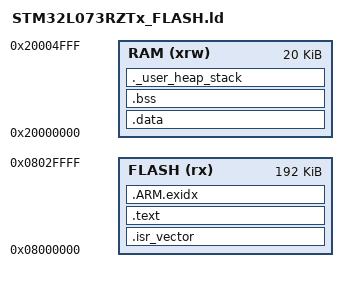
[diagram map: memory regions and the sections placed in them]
/* STM32L073RZT6: 192 KiB Flash and 20 KiB SRAM. */
ENTRY(Reset_Handler)

MEMORY
{
    FLASH (rx)  : ORIGIN = 0x08000000, LENGTH = 192K
    RAM   (xrw) : ORIGIN = 0x20000000, LENGTH = 20K
}

_estack = ORIGIN(RAM) + LENGTH(RAM);

SECTIONS
{
    .isr_vector :
    {
        . = ALIGN(4);
        KEEP(*(.isr_vector))
        . = ALIGN(4);
    } > FLASH

    .text :
    {
        . = ALIGN(4);
        *(.text*)
        *(.rodata*)
        . = ALIGN(4);
        _etext = .;
    } > FLASH

    .ARM.exidx :
    {
        . = ALIGN(4);
        *(.ARM.exidx*)
        . = ALIGN(4);
    } > FLASH

    .data : AT(_etext)
    {
        . = ALIGN(4);
        _sdata = .;
        *(.data*)
        . = ALIGN(4);
        _edata = .;
    } > RAM

    .bss (NOLOAD) :
    {
        . = ALIGN(4);
        _sbss = .;
        *(.bss*)
        *(COMMON)
        . = ALIGN(4);
        _ebss = .;
    } > RAM

    ._user_heap_stack (NOLOAD) :
    {
        . = ALIGN(8);
        . = . + 0x400;
        . = ALIGN(8);
    } > RAM

    /DISCARD/ :
    {
        *(.note*)
        *(.comment*)
    }
}

ASSERT(_ebss <= ORIGIN(RAM) + LENGTH(RAM), "RAM overflow")
